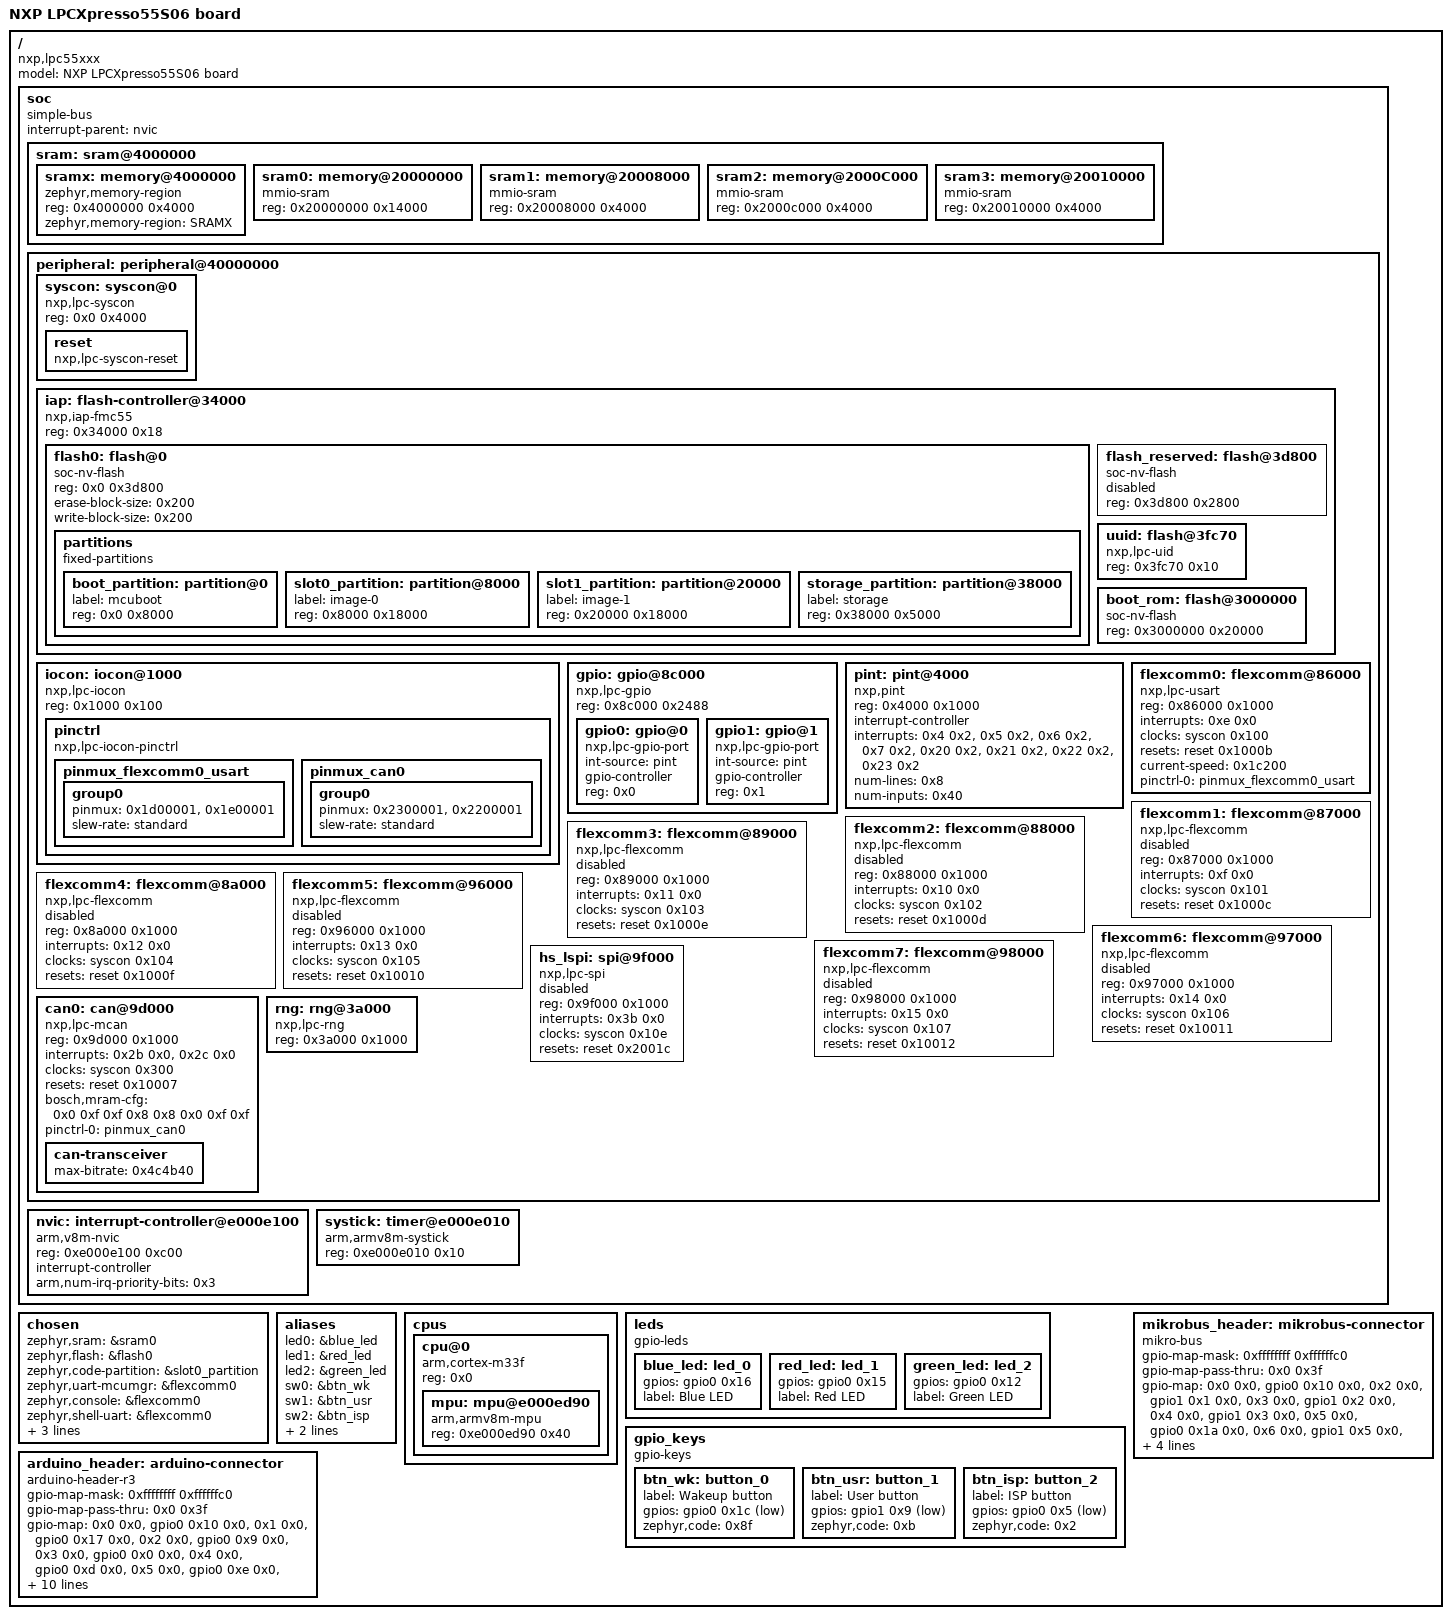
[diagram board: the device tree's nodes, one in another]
/dts-v1/;

/* node '/' defined in zephyr/dts/arm/nxp/nxp_lpc55S06_ns.dtsi:7 */
/ {
	#address-cells = < 0x1 >;            /* in zephyr/dts/common/skeleton.dtsi:10 */
	#size-cells = < 0x1 >;               /* in zephyr/dts/common/skeleton.dtsi:11 */
	model = "NXP LPCXpresso55S06 board"; /* in zephyr/boards/nxp/lpcxpresso55s06/lpcxpresso55s06.dts:13 */
	compatible = "nxp,lpc55xxx",
	             "nxp,lpc";              /* in zephyr/boards/nxp/lpcxpresso55s06/lpcxpresso55s06.dts:14 */

	/* node '/soc' defined in zephyr/dts/arm/nxp/nxp_lpc55S06_ns.dtsi:8 */
	soc {
		#address-cells = < 0x1 >;     /* in zephyr/dts/arm/armv8-m.dtsi:7 */
		#size-cells = < 0x1 >;        /* in zephyr/dts/arm/armv8-m.dtsi:8 */
		compatible = "simple-bus";    /* in zephyr/dts/arm/armv8-m.dtsi:9 */
		interrupt-parent = < &nvic >; /* in zephyr/dts/arm/armv8-m.dtsi:10 */
		ranges;                       /* in zephyr/dts/arm/armv8-m.dtsi:11 */

		/* node '/soc/sram@4000000' defined in zephyr/dts/arm/nxp/nxp_lpc55S06_ns.dtsi:9 */
		sram: sram@4000000 {
			ranges = < 0x4000000 0x4000000 0x20000000 >; /* in zephyr/dts/arm/nxp/nxp_lpc55S06_ns.dtsi:10 */
			#address-cells = < 0x1 >;                    /* in zephyr/dts/arm/nxp/nxp_lpc55S0x_common.dtsi:34 */
			#size-cells = < 0x1 >;                       /* in zephyr/dts/arm/nxp/nxp_lpc55S0x_common.dtsi:35 */

			/* node '/soc/sram@4000000/memory@4000000' defined in zephyr/dts/arm/nxp/nxp_lpc55S0x_common.dtsi:43 */
			sramx: memory@4000000 {
				compatible = "zephyr,memory-region",
				             "mmio-sram";            /* in zephyr/dts/arm/nxp/nxp_lpc55S06_ns.dtsi:22 */
				reg = < 0x4000000 0x4000 >;          /* in zephyr/dts/arm/nxp/nxp_lpc55S06_ns.dtsi:23 */
				zephyr,memory-region = "SRAMX";      /* in zephyr/dts/arm/nxp/nxp_lpc55S06_ns.dtsi:24 */
			};

			/* node '/soc/sram@4000000/memory@20000000' defined in zephyr/dts/arm/nxp/nxp_lpc55S0x_common.dtsi:48 */
			sram0: memory@20000000 {
				compatible = "mmio-sram";     /* in zephyr/dts/arm/nxp/nxp_lpc55S06_ns.dtsi:36 */
				reg = < 0x20000000 0x14000 >; /* in zephyr/dts/arm/nxp/nxp_lpc55S06_ns.dtsi:37 */
			};

			/* node '/soc/sram@4000000/memory@20008000' defined in zephyr/dts/arm/nxp/nxp_lpc55S0x_common.dtsi:53 */
			sram1: memory@20008000 {
				compatible = "mmio-sram";    /* in zephyr/dts/arm/nxp/nxp_lpc55S0x_common.dtsi:54 */
				reg = < 0x20008000 0x4000 >; /* in zephyr/dts/arm/nxp/nxp_lpc55S0x_common.dtsi:55 */
			};

			/* node '/soc/sram@4000000/memory@2000C000' defined in zephyr/dts/arm/nxp/nxp_lpc55S0x_common.dtsi:58 */
			sram2: memory@2000C000 {
				compatible = "mmio-sram";    /* in zephyr/dts/arm/nxp/nxp_lpc55S0x_common.dtsi:59 */
				reg = < 0x2000c000 0x4000 >; /* in zephyr/dts/arm/nxp/nxp_lpc55S0x_common.dtsi:60 */
			};

			/* node '/soc/sram@4000000/memory@20010000' defined in zephyr/dts/arm/nxp/nxp_lpc55S0x_common.dtsi:63 */
			sram3: memory@20010000 {
				compatible = "mmio-sram";    /* in zephyr/dts/arm/nxp/nxp_lpc55S0x_common.dtsi:64 */
				reg = < 0x20010000 0x4000 >; /* in zephyr/dts/arm/nxp/nxp_lpc55S0x_common.dtsi:65 */
			};
		};

		/* node '/soc/peripheral@40000000' defined in zephyr/dts/arm/nxp/nxp_lpc55S06_ns.dtsi:13 */
		peripheral: peripheral@40000000 {
			ranges = < 0x0 0x40000000 0x10000000 >; /* in zephyr/dts/arm/nxp/nxp_lpc55S06_ns.dtsi:14 */
			#address-cells = < 0x1 >;               /* in zephyr/dts/arm/nxp/nxp_lpc55S0x_common.dtsi:70 */
			#size-cells = < 0x1 >;                  /* in zephyr/dts/arm/nxp/nxp_lpc55S0x_common.dtsi:71 */

			/* node '/soc/peripheral@40000000/syscon@0' defined in zephyr/dts/arm/nxp/nxp_lpc55S0x_common.dtsi:73 */
			syscon: syscon@0 {
				compatible = "nxp,lpc-syscon"; /* in zephyr/dts/arm/nxp/nxp_lpc55S0x_common.dtsi:74 */
				reg = < 0x0 0x4000 >;          /* in zephyr/dts/arm/nxp/nxp_lpc55S0x_common.dtsi:75 */
				#clock-cells = < 0x1 >;        /* in zephyr/dts/arm/nxp/nxp_lpc55S0x_common.dtsi:76 */
				phandle = < 0x2 >;             /* in zephyr/dts/arm/nxp/nxp_lpc55S0x_common.dtsi:166 */

				/* node '/soc/peripheral@40000000/syscon@0/reset' defined in zephyr/dts/arm/nxp/nxp_lpc55S0x_common.dtsi:78 */
				reset: reset {
					compatible = "nxp,lpc-syscon-reset"; /* in zephyr/dts/arm/nxp/nxp_lpc55S0x_common.dtsi:79 */
					#reset-cells = < 0x1 >;              /* in zephyr/dts/arm/nxp/nxp_lpc55S0x_common.dtsi:80 */
					phandle = < 0x3 >;                   /* in zephyr/dts/arm/nxp/nxp_lpc55S0x_common.dtsi:167 */
				};
			};

			/* node '/soc/peripheral@40000000/flash-controller@34000' defined in zephyr/dts/arm/nxp/nxp_lpc55S0x_common.dtsi:84 */
			iap: flash-controller@34000 {
				compatible = "nxp,iap-fmc55"; /* in zephyr/dts/arm/nxp/nxp_lpc55S0x_common.dtsi:85 */
				reg = < 0x34000 0x18 >;       /* in zephyr/dts/arm/nxp/nxp_lpc55S0x_common.dtsi:86 */
				#address-cells = < 0x1 >;     /* in zephyr/dts/arm/nxp/nxp_lpc55S0x_common.dtsi:88 */
				#size-cells = < 0x1 >;        /* in zephyr/dts/arm/nxp/nxp_lpc55S0x_common.dtsi:89 */
				status = "okay";              /* in zephyr/dts/arm/nxp/nxp_lpc55S06_ns.dtsi:28 */

				/* node '/soc/peripheral@40000000/flash-controller@34000/flash@0' defined in zephyr/dts/arm/nxp/nxp_lpc55S0x_common.dtsi:91 */
				flash0: flash@0 {
					compatible = "soc-nv-flash";  /* in zephyr/dts/arm/nxp/nxp_lpc55S0x_common.dtsi:92 */
					reg = < 0x0 0x3d800 >;        /* in zephyr/dts/arm/nxp/nxp_lpc55S0x_common.dtsi:93 */
					erase-block-size = < 0x200 >; /* in zephyr/dts/arm/nxp/nxp_lpc55S0x_common.dtsi:94 */
					write-block-size = < 0x200 >; /* in zephyr/dts/arm/nxp/nxp_lpc55S0x_common.dtsi:95 */

					/* node '/soc/peripheral@40000000/flash-controller@34000/flash@0/partitions' defined in zephyr/boards/nxp/lpcxpresso55s06/lpcxpresso55s06_common.dtsi:129 */
					partitions {
						compatible = "fixed-partitions"; /* in zephyr/boards/nxp/lpcxpresso55s06/lpcxpresso55s06_common.dtsi:130 */
						#address-cells = < 0x1 >;        /* in zephyr/boards/nxp/lpcxpresso55s06/lpcxpresso55s06_common.dtsi:131 */
						#size-cells = < 0x1 >;           /* in zephyr/boards/nxp/lpcxpresso55s06/lpcxpresso55s06_common.dtsi:132 */

						/* node '/soc/peripheral@40000000/flash-controller@34000/flash@0/partitions/partition@0' defined in zephyr/boards/nxp/lpcxpresso55s06/lpcxpresso55s06_common.dtsi:134 */
						boot_partition: partition@0 {
							label = "mcuboot";    /* in zephyr/boards/nxp/lpcxpresso55s06/lpcxpresso55s06_common.dtsi:135 */
							reg = < 0x0 0x8000 >; /* in zephyr/boards/nxp/lpcxpresso55s06/lpcxpresso55s06_common.dtsi:136 */
						};

						/* node '/soc/peripheral@40000000/flash-controller@34000/flash@0/partitions/partition@8000' defined in zephyr/boards/nxp/lpcxpresso55s06/lpcxpresso55s06_common.dtsi:139 */
						slot0_partition: partition@8000 {
							label = "image-0";        /* in zephyr/boards/nxp/lpcxpresso55s06/lpcxpresso55s06_common.dtsi:140 */
							reg = < 0x8000 0x18000 >; /* in zephyr/boards/nxp/lpcxpresso55s06/lpcxpresso55s06_common.dtsi:141 */
						};

						/* node '/soc/peripheral@40000000/flash-controller@34000/flash@0/partitions/partition@20000' defined in zephyr/boards/nxp/lpcxpresso55s06/lpcxpresso55s06_common.dtsi:144 */
						slot1_partition: partition@20000 {
							label = "image-1";         /* in zephyr/boards/nxp/lpcxpresso55s06/lpcxpresso55s06_common.dtsi:145 */
							reg = < 0x20000 0x18000 >; /* in zephyr/boards/nxp/lpcxpresso55s06/lpcxpresso55s06_common.dtsi:146 */
						};

						/* node '/soc/peripheral@40000000/flash-controller@34000/flash@0/partitions/partition@38000' defined in zephyr/boards/nxp/lpcxpresso55s06/lpcxpresso55s06_common.dtsi:149 */
						storage_partition: partition@38000 {
							label = "storage";        /* in zephyr/boards/nxp/lpcxpresso55s06/lpcxpresso55s06_common.dtsi:150 */
							reg = < 0x38000 0x5000 >; /* in zephyr/boards/nxp/lpcxpresso55s06/lpcxpresso55s06_common.dtsi:151 */
						};
					};
				};

				/* node '/soc/peripheral@40000000/flash-controller@34000/flash@3d800' defined in zephyr/dts/arm/nxp/nxp_lpc55S0x_common.dtsi:98 */
				flash_reserved: flash@3d800 {
					compatible = "soc-nv-flash"; /* in zephyr/dts/arm/nxp/nxp_lpc55S0x_common.dtsi:99 */
					reg = < 0x3d800 0x2800 >;    /* in zephyr/dts/arm/nxp/nxp_lpc55S0x_common.dtsi:100 */
					status = "disabled";         /* in zephyr/dts/arm/nxp/nxp_lpc55S0x_common.dtsi:101 */
				};

				/* node '/soc/peripheral@40000000/flash-controller@34000/flash@3fc70' defined in zephyr/dts/arm/nxp/nxp_lpc55S0x_common.dtsi:104 */
				uuid: flash@3fc70 {
					compatible = "nxp,lpc-uid"; /* in zephyr/dts/arm/nxp/nxp_lpc55S0x_common.dtsi:105 */
					reg = < 0x3fc70 0x10 >;     /* in zephyr/dts/arm/nxp/nxp_lpc55S0x_common.dtsi:106 */
				};

				/* node '/soc/peripheral@40000000/flash-controller@34000/flash@3000000' defined in zephyr/dts/arm/nxp/nxp_lpc55S0x_common.dtsi:109 */
				boot_rom: flash@3000000 {
					compatible = "soc-nv-flash"; /* in zephyr/dts/arm/nxp/nxp_lpc55S0x_common.dtsi:110 */
					reg = < 0x3000000 0x20000 >; /* in zephyr/dts/arm/nxp/nxp_lpc55S0x_common.dtsi:111 */
				};
			};

			/* node '/soc/peripheral@40000000/iocon@1000' defined in zephyr/dts/arm/nxp/nxp_lpc55S0x_common.dtsi:115 */
			iocon: iocon@1000 {
				compatible = "nxp,lpc-iocon";  /* in zephyr/dts/arm/nxp/nxp_lpc55S0x_common.dtsi:116 */
				reg = < 0x1000 0x100 >;        /* in zephyr/dts/arm/nxp/nxp_lpc55S0x_common.dtsi:117 */
				#address-cells = < 0x1 >;      /* in zephyr/dts/arm/nxp/nxp_lpc55S0x_common.dtsi:118 */
				#size-cells = < 0x1 >;         /* in zephyr/dts/arm/nxp/nxp_lpc55S0x_common.dtsi:119 */
				ranges = < 0x0 0x1000 0x100 >; /* in zephyr/dts/arm/nxp/nxp_lpc55S0x_common.dtsi:120 */

				/* node '/soc/peripheral@40000000/iocon@1000/pinctrl' defined in zephyr/dts/arm/nxp/nxp_lpc55S0x_common.dtsi:122 */
				pinctrl: pinctrl {
					compatible = "nxp,lpc-iocon-pinctrl"; /* in zephyr/dts/arm/nxp/nxp_lpc55S0x_common.dtsi:123 */

					/* node '/soc/peripheral@40000000/iocon@1000/pinctrl/pinmux_flexcomm0_usart' defined in zephyr/boards/nxp/lpcxpresso55s06/lpcxpresso55s06-pinctrl.dtsi:12 */
					pinmux_flexcomm0_usart: pinmux_flexcomm0_usart {
						phandle = < 0x4 >; /* in zephyr/boards/nxp/lpcxpresso55s06/lpcxpresso55s06_common.dtsi:161 */

						/* node '/soc/peripheral@40000000/iocon@1000/pinctrl/pinmux_flexcomm0_usart/group0' defined in zephyr/boards/nxp/lpcxpresso55s06/lpcxpresso55s06-pinctrl.dtsi:13 */
						group0 {
							pinmux = < 0x1d00001 >,
							         < 0x1e00001 >; /* in zephyr/boards/nxp/lpcxpresso55s06/lpcxpresso55s06-pinctrl.dtsi:14 */
							slew-rate = "standard"; /* in zephyr/boards/nxp/lpcxpresso55s06/lpcxpresso55s06-pinctrl.dtsi:16 */
						};
					};

					/* node '/soc/peripheral@40000000/iocon@1000/pinctrl/pinmux_can0' defined in zephyr/boards/nxp/lpcxpresso55s06/lpcxpresso55s06-pinctrl.dtsi:20 */
					pinmux_can0: pinmux_can0 {
						phandle = < 0x5 >; /* in zephyr/boards/nxp/lpcxpresso55s06/lpcxpresso55s06_common.dtsi:167 */

						/* node '/soc/peripheral@40000000/iocon@1000/pinctrl/pinmux_can0/group0' defined in zephyr/boards/nxp/lpcxpresso55s06/lpcxpresso55s06-pinctrl.dtsi:21 */
						group0 {
							pinmux = < 0x2300001 >,
							         < 0x2200001 >; /* in zephyr/boards/nxp/lpcxpresso55s06/lpcxpresso55s06-pinctrl.dtsi:22 */
							slew-rate = "standard"; /* in zephyr/boards/nxp/lpcxpresso55s06/lpcxpresso55s06-pinctrl.dtsi:24 */
						};
					};
				};
			};

			/* node '/soc/peripheral@40000000/gpio@8c000' defined in zephyr/dts/arm/nxp/nxp_lpc55S0x_common.dtsi:127 */
			gpio: gpio@8c000 {
				compatible = "nxp,lpc-gpio"; /* in zephyr/dts/arm/nxp/nxp_lpc55S0x_common.dtsi:128 */
				reg = < 0x8c000 0x2488 >;    /* in zephyr/dts/arm/nxp/nxp_lpc55S0x_common.dtsi:129 */
				#address-cells = < 0x1 >;    /* in zephyr/dts/arm/nxp/nxp_lpc55S0x_common.dtsi:130 */
				#size-cells = < 0x0 >;       /* in zephyr/dts/arm/nxp/nxp_lpc55S0x_common.dtsi:131 */

				/* node '/soc/peripheral@40000000/gpio@8c000/gpio@0' defined in zephyr/dts/arm/nxp/nxp_lpc55S0x_common.dtsi:133 */
				gpio0: gpio@0 {
					compatible = "nxp,lpc-gpio-port"; /* in zephyr/dts/arm/nxp/nxp_lpc55S0x_common.dtsi:134 */
					int-source = "pint";              /* in zephyr/dts/arm/nxp/nxp_lpc55S0x_common.dtsi:135 */
					gpio-controller;                  /* in zephyr/dts/arm/nxp/nxp_lpc55S0x_common.dtsi:136 */
					#gpio-cells = < 0x2 >;            /* in zephyr/dts/arm/nxp/nxp_lpc55S0x_common.dtsi:137 */
					reg = < 0x0 >;                    /* in zephyr/dts/arm/nxp/nxp_lpc55S0x_common.dtsi:138 */
					phandle = < 0x6 >;                /* in zephyr/boards/nxp/lpcxpresso55s06/lpcxpresso55s06_common.dtsi:40 */
				};

				/* node '/soc/peripheral@40000000/gpio@8c000/gpio@1' defined in zephyr/dts/arm/nxp/nxp_lpc55S0x_common.dtsi:141 */
				gpio1: gpio@1 {
					compatible = "nxp,lpc-gpio-port"; /* in zephyr/dts/arm/nxp/nxp_lpc55S0x_common.dtsi:142 */
					int-source = "pint";              /* in zephyr/dts/arm/nxp/nxp_lpc55S0x_common.dtsi:143 */
					gpio-controller;                  /* in zephyr/dts/arm/nxp/nxp_lpc55S0x_common.dtsi:144 */
					#gpio-cells = < 0x2 >;            /* in zephyr/dts/arm/nxp/nxp_lpc55S0x_common.dtsi:145 */
					reg = < 0x1 >;                    /* in zephyr/dts/arm/nxp/nxp_lpc55S0x_common.dtsi:146 */
					phandle = < 0x7 >;                /* in zephyr/boards/nxp/lpcxpresso55s06/lpcxpresso55s06_common.dtsi:66 */
				};
			};

			/* node '/soc/peripheral@40000000/pint@4000' defined in zephyr/dts/arm/nxp/nxp_lpc55S0x_common.dtsi:150 */
			pint: pint@4000 {
				compatible = "nxp,pint";    /* in zephyr/dts/arm/nxp/nxp_lpc55S0x_common.dtsi:151 */
				reg = < 0x4000 0x1000 >;    /* in zephyr/dts/arm/nxp/nxp_lpc55S0x_common.dtsi:152 */
				interrupt-controller;       /* in zephyr/dts/arm/nxp/nxp_lpc55S0x_common.dtsi:153 */
				#interrupt-cells = < 0x1 >; /* in zephyr/dts/arm/nxp/nxp_lpc55S0x_common.dtsi:154 */
				#address-cells = < 0x0 >;   /* in zephyr/dts/arm/nxp/nxp_lpc55S0x_common.dtsi:155 */
				interrupts = < 0x4 0x2 >,
				             < 0x5 0x2 >,
				             < 0x6 0x2 >,
				             < 0x7 0x2 >,
				             < 0x20 0x2 >,
				             < 0x21 0x2 >,
				             < 0x22 0x2 >,
				             < 0x23 0x2 >;  /* in zephyr/dts/arm/nxp/nxp_lpc55S0x_common.dtsi:156 */
				num-lines = < 0x8 >;        /* in zephyr/dts/arm/nxp/nxp_lpc55S0x_common.dtsi:158 */
				num-inputs = < 0x40 >;      /* in zephyr/dts/arm/nxp/nxp_lpc55S0x_common.dtsi:159 */
			};

			/* node '/soc/peripheral@40000000/flexcomm@86000' defined in zephyr/dts/arm/nxp/nxp_lpc55S0x_common.dtsi:162 */
			flexcomm0: flexcomm@86000 {
				reg = < 0x86000 0x1000 >;                /* in zephyr/dts/arm/nxp/nxp_lpc55S0x_common.dtsi:164 */
				interrupts = < 0xe 0x0 >;                /* in zephyr/dts/arm/nxp/nxp_lpc55S0x_common.dtsi:165 */
				clocks = < &syscon 0x100 >;              /* in zephyr/dts/arm/nxp/nxp_lpc55S0x_common.dtsi:166 */
				resets = < &reset 0x1000b >;             /* in zephyr/dts/arm/nxp/nxp_lpc55S0x_common.dtsi:167 */
				status = "okay";                         /* in zephyr/boards/nxp/lpcxpresso55s06/lpcxpresso55s06_common.dtsi:158 */
				compatible = "nxp,lpc-usart";            /* in zephyr/boards/nxp/lpcxpresso55s06/lpcxpresso55s06_common.dtsi:159 */
				current-speed = < 0x1c200 >;             /* in zephyr/boards/nxp/lpcxpresso55s06/lpcxpresso55s06_common.dtsi:160 */
				pinctrl-0 = < &pinmux_flexcomm0_usart >; /* in zephyr/boards/nxp/lpcxpresso55s06/lpcxpresso55s06_common.dtsi:161 */
				pinctrl-names = "default";               /* in zephyr/boards/nxp/lpcxpresso55s06/lpcxpresso55s06_common.dtsi:162 */
			};

			/* node '/soc/peripheral@40000000/flexcomm@87000' defined in zephyr/dts/arm/nxp/nxp_lpc55S0x_common.dtsi:171 */
			flexcomm1: flexcomm@87000 {
				compatible = "nxp,lpc-flexcomm"; /* in zephyr/dts/arm/nxp/nxp_lpc55S0x_common.dtsi:172 */
				reg = < 0x87000 0x1000 >;        /* in zephyr/dts/arm/nxp/nxp_lpc55S0x_common.dtsi:173 */
				interrupts = < 0xf 0x0 >;        /* in zephyr/dts/arm/nxp/nxp_lpc55S0x_common.dtsi:174 */
				clocks = < &syscon 0x101 >;      /* in zephyr/dts/arm/nxp/nxp_lpc55S0x_common.dtsi:175 */
				resets = < &reset 0x1000c >;     /* in zephyr/dts/arm/nxp/nxp_lpc55S0x_common.dtsi:176 */
				status = "disabled";             /* in zephyr/dts/arm/nxp/nxp_lpc55S0x_common.dtsi:177 */
			};

			/* node '/soc/peripheral@40000000/flexcomm@88000' defined in zephyr/dts/arm/nxp/nxp_lpc55S0x_common.dtsi:180 */
			flexcomm2: flexcomm@88000 {
				compatible = "nxp,lpc-flexcomm"; /* in zephyr/dts/arm/nxp/nxp_lpc55S0x_common.dtsi:181 */
				reg = < 0x88000 0x1000 >;        /* in zephyr/dts/arm/nxp/nxp_lpc55S0x_common.dtsi:182 */
				interrupts = < 0x10 0x0 >;       /* in zephyr/dts/arm/nxp/nxp_lpc55S0x_common.dtsi:183 */
				clocks = < &syscon 0x102 >;      /* in zephyr/dts/arm/nxp/nxp_lpc55S0x_common.dtsi:184 */
				resets = < &reset 0x1000d >;     /* in zephyr/dts/arm/nxp/nxp_lpc55S0x_common.dtsi:185 */
				status = "disabled";             /* in zephyr/dts/arm/nxp/nxp_lpc55S0x_common.dtsi:186 */
			};

			/* node '/soc/peripheral@40000000/flexcomm@89000' defined in zephyr/dts/arm/nxp/nxp_lpc55S0x_common.dtsi:189 */
			flexcomm3: flexcomm@89000 {
				compatible = "nxp,lpc-flexcomm"; /* in zephyr/dts/arm/nxp/nxp_lpc55S0x_common.dtsi:190 */
				reg = < 0x89000 0x1000 >;        /* in zephyr/dts/arm/nxp/nxp_lpc55S0x_common.dtsi:191 */
				interrupts = < 0x11 0x0 >;       /* in zephyr/dts/arm/nxp/nxp_lpc55S0x_common.dtsi:192 */
				clocks = < &syscon 0x103 >;      /* in zephyr/dts/arm/nxp/nxp_lpc55S0x_common.dtsi:193 */
				resets = < &reset 0x1000e >;     /* in zephyr/dts/arm/nxp/nxp_lpc55S0x_common.dtsi:194 */
				status = "disabled";             /* in zephyr/dts/arm/nxp/nxp_lpc55S0x_common.dtsi:195 */
			};

			/* node '/soc/peripheral@40000000/flexcomm@8a000' defined in zephyr/dts/arm/nxp/nxp_lpc55S0x_common.dtsi:198 */
			flexcomm4: flexcomm@8a000 {
				compatible = "nxp,lpc-flexcomm"; /* in zephyr/dts/arm/nxp/nxp_lpc55S0x_common.dtsi:199 */
				reg = < 0x8a000 0x1000 >;        /* in zephyr/dts/arm/nxp/nxp_lpc55S0x_common.dtsi:200 */
				interrupts = < 0x12 0x0 >;       /* in zephyr/dts/arm/nxp/nxp_lpc55S0x_common.dtsi:201 */
				clocks = < &syscon 0x104 >;      /* in zephyr/dts/arm/nxp/nxp_lpc55S0x_common.dtsi:202 */
				resets = < &reset 0x1000f >;     /* in zephyr/dts/arm/nxp/nxp_lpc55S0x_common.dtsi:203 */
				status = "disabled";             /* in zephyr/dts/arm/nxp/nxp_lpc55S0x_common.dtsi:204 */
			};

			/* node '/soc/peripheral@40000000/flexcomm@96000' defined in zephyr/dts/arm/nxp/nxp_lpc55S0x_common.dtsi:207 */
			flexcomm5: flexcomm@96000 {
				compatible = "nxp,lpc-flexcomm"; /* in zephyr/dts/arm/nxp/nxp_lpc55S0x_common.dtsi:208 */
				reg = < 0x96000 0x1000 >;        /* in zephyr/dts/arm/nxp/nxp_lpc55S0x_common.dtsi:209 */
				interrupts = < 0x13 0x0 >;       /* in zephyr/dts/arm/nxp/nxp_lpc55S0x_common.dtsi:210 */
				clocks = < &syscon 0x105 >;      /* in zephyr/dts/arm/nxp/nxp_lpc55S0x_common.dtsi:211 */
				resets = < &reset 0x10010 >;     /* in zephyr/dts/arm/nxp/nxp_lpc55S0x_common.dtsi:212 */
				status = "disabled";             /* in zephyr/dts/arm/nxp/nxp_lpc55S0x_common.dtsi:213 */
			};

			/* node '/soc/peripheral@40000000/flexcomm@97000' defined in zephyr/dts/arm/nxp/nxp_lpc55S0x_common.dtsi:216 */
			flexcomm6: flexcomm@97000 {
				compatible = "nxp,lpc-flexcomm"; /* in zephyr/dts/arm/nxp/nxp_lpc55S0x_common.dtsi:217 */
				reg = < 0x97000 0x1000 >;        /* in zephyr/dts/arm/nxp/nxp_lpc55S0x_common.dtsi:218 */
				interrupts = < 0x14 0x0 >;       /* in zephyr/dts/arm/nxp/nxp_lpc55S0x_common.dtsi:219 */
				clocks = < &syscon 0x106 >;      /* in zephyr/dts/arm/nxp/nxp_lpc55S0x_common.dtsi:220 */
				resets = < &reset 0x10011 >;     /* in zephyr/dts/arm/nxp/nxp_lpc55S0x_common.dtsi:221 */
				status = "disabled";             /* in zephyr/dts/arm/nxp/nxp_lpc55S0x_common.dtsi:222 */
			};

			/* node '/soc/peripheral@40000000/flexcomm@98000' defined in zephyr/dts/arm/nxp/nxp_lpc55S0x_common.dtsi:225 */
			flexcomm7: flexcomm@98000 {
				compatible = "nxp,lpc-flexcomm"; /* in zephyr/dts/arm/nxp/nxp_lpc55S0x_common.dtsi:226 */
				reg = < 0x98000 0x1000 >;        /* in zephyr/dts/arm/nxp/nxp_lpc55S0x_common.dtsi:227 */
				interrupts = < 0x15 0x0 >;       /* in zephyr/dts/arm/nxp/nxp_lpc55S0x_common.dtsi:228 */
				clocks = < &syscon 0x107 >;      /* in zephyr/dts/arm/nxp/nxp_lpc55S0x_common.dtsi:229 */
				resets = < &reset 0x10012 >;     /* in zephyr/dts/arm/nxp/nxp_lpc55S0x_common.dtsi:230 */
				status = "disabled";             /* in zephyr/dts/arm/nxp/nxp_lpc55S0x_common.dtsi:231 */
			};

			/* node '/soc/peripheral@40000000/spi@9f000' defined in zephyr/dts/arm/nxp/nxp_lpc55S0x_common.dtsi:234 */
			hs_lspi: spi@9f000 {
				compatible = "nxp,lpc-spi";  /* in zephyr/dts/arm/nxp/nxp_lpc55S0x_common.dtsi:235 */
				reg = < 0x9f000 0x1000 >;    /* in zephyr/dts/arm/nxp/nxp_lpc55S0x_common.dtsi:236 */
				interrupts = < 0x3b 0x0 >;   /* in zephyr/dts/arm/nxp/nxp_lpc55S0x_common.dtsi:237 */
				clocks = < &syscon 0x10e >;  /* in zephyr/dts/arm/nxp/nxp_lpc55S0x_common.dtsi:238 */
				resets = < &reset 0x2001c >; /* in zephyr/dts/arm/nxp/nxp_lpc55S0x_common.dtsi:239 */
				status = "disabled";         /* in zephyr/dts/arm/nxp/nxp_lpc55S0x_common.dtsi:240 */
				#address-cells = < 0x1 >;    /* in zephyr/dts/arm/nxp/nxp_lpc55S0x_common.dtsi:241 */
				#size-cells = < 0x0 >;       /* in zephyr/dts/arm/nxp/nxp_lpc55S0x_common.dtsi:242 */
			};

			/* node '/soc/peripheral@40000000/can@9d000' defined in zephyr/dts/arm/nxp/nxp_lpc55S0x_common.dtsi:245 */
			can0: can@9d000 {
				compatible = "nxp,lpc-mcan";                          /* in zephyr/dts/arm/nxp/nxp_lpc55S0x_common.dtsi:246 */
				reg = < 0x9d000 0x1000 >;                             /* in zephyr/dts/arm/nxp/nxp_lpc55S0x_common.dtsi:247 */
				interrupts = < 0x2b 0x0 >,
				             < 0x2c 0x0 >;                            /* in zephyr/dts/arm/nxp/nxp_lpc55S0x_common.dtsi:248 */
				interrupt-names = "int0",
				                  "int1";                             /* in zephyr/dts/arm/nxp/nxp_lpc55S0x_common.dtsi:249 */
				clocks = < &syscon 0x300 >;                           /* in zephyr/dts/arm/nxp/nxp_lpc55S0x_common.dtsi:250 */
				resets = < &reset 0x10007 >;                          /* in zephyr/dts/arm/nxp/nxp_lpc55S0x_common.dtsi:251 */
				bosch,mram-cfg = < 0x0 0xf 0xf 0x8 0x8 0x0 0xf 0xf >; /* in zephyr/dts/arm/nxp/nxp_lpc55S0x_common.dtsi:252 */
				status = "okay";                                      /* in zephyr/boards/nxp/lpcxpresso55s06/lpcxpresso55s06_common.dtsi:166 */
				pinctrl-0 = < &pinmux_can0 >;                         /* in zephyr/boards/nxp/lpcxpresso55s06/lpcxpresso55s06_common.dtsi:167 */
				pinctrl-names = "default";                            /* in zephyr/boards/nxp/lpcxpresso55s06/lpcxpresso55s06_common.dtsi:168 */

				/* node '/soc/peripheral@40000000/can@9d000/can-transceiver' defined in zephyr/boards/nxp/lpcxpresso55s06/lpcxpresso55s06_common.dtsi:170 */
				can-transceiver {
					max-bitrate = < 0x4c4b40 >; /* in zephyr/boards/nxp/lpcxpresso55s06/lpcxpresso55s06_common.dtsi:171 */
				};
			};

			/* node '/soc/peripheral@40000000/rng@3a000' defined in zephyr/dts/arm/nxp/nxp_lpc55S0x_common.dtsi:256 */
			rng: rng@3a000 {
				compatible = "nxp,lpc-rng"; /* in zephyr/dts/arm/nxp/nxp_lpc55S0x_common.dtsi:257 */
				reg = < 0x3a000 0x1000 >;   /* in zephyr/dts/arm/nxp/nxp_lpc55S0x_common.dtsi:258 */
				status = "okay";            /* in zephyr/dts/arm/nxp/nxp_lpc55S0x_common.dtsi:259 */
			};
		};

		/* node '/soc/interrupt-controller@e000e100' defined in zephyr/dts/arm/armv8-m.dtsi:13 */
		nvic: interrupt-controller@e000e100 {
			#address-cells = < 0x1 >;            /* in zephyr/dts/arm/armv8-m.dtsi:14 */
			compatible = "arm,v8m-nvic";         /* in zephyr/dts/arm/armv8-m.dtsi:15 */
			reg = < 0xe000e100 0xc00 >;          /* in zephyr/dts/arm/armv8-m.dtsi:16 */
			interrupt-controller;                /* in zephyr/dts/arm/armv8-m.dtsi:17 */
			#interrupt-cells = < 0x2 >;          /* in zephyr/dts/arm/armv8-m.dtsi:18 */
			arm,num-irq-priority-bits = < 0x3 >; /* in zephyr/dts/arm/nxp/nxp_lpc55S0x_common.dtsi:264 */
			phandle = < 0x1 >;                   /* in zephyr/dts/arm/armv8-m.dtsi:10 */
		};

		/* node '/soc/timer@e000e010' defined in zephyr/dts/arm/armv8-m.dtsi:21 */
		systick: timer@e000e010 {
			compatible = "arm,armv8m-systick"; /* in zephyr/dts/arm/armv8-m.dtsi:22 */
			reg = < 0xe000e010 0x10 >;         /* in zephyr/dts/arm/armv8-m.dtsi:23 */
		};
	};

	/* node '/chosen' defined in zephyr/dts/common/skeleton.dtsi:13 */
	chosen {
		zephyr,sram = &sram0;                     /* in zephyr/boards/nxp/lpcxpresso55s06/lpcxpresso55s06_common.dtsi:14 */
		zephyr,flash = &flash0;                   /* in zephyr/boards/nxp/lpcxpresso55s06/lpcxpresso55s06_common.dtsi:15 */
		zephyr,code-partition = &slot0_partition; /* in zephyr/boards/nxp/lpcxpresso55s06/lpcxpresso55s06_common.dtsi:16 */
		zephyr,uart-mcumgr = &flexcomm0;          /* in zephyr/boards/nxp/lpcxpresso55s06/lpcxpresso55s06_common.dtsi:17 */
		zephyr,console = &flexcomm0;              /* in zephyr/boards/nxp/lpcxpresso55s06/lpcxpresso55s06_common.dtsi:18 */
		zephyr,shell-uart = &flexcomm0;           /* in zephyr/boards/nxp/lpcxpresso55s06/lpcxpresso55s06_common.dtsi:19 */
		zephyr,entropy = &rng;                    /* in zephyr/boards/nxp/lpcxpresso55s06/lpcxpresso55s06_common.dtsi:20 */
		zephyr,flash-controller = &iap;           /* in zephyr/boards/nxp/lpcxpresso55s06/lpcxpresso55s06_common.dtsi:21 */
		zephyr,canbus = &can0;                    /* in zephyr/boards/nxp/lpcxpresso55s06/lpcxpresso55s06_common.dtsi:22 */
	};

	/* node '/aliases' defined in zephyr/dts/common/skeleton.dtsi:15 */
	aliases {
		led0 = &blue_led;          /* in zephyr/boards/nxp/lpcxpresso55s06/lpcxpresso55s06_common.dtsi:26 */
		led1 = &red_led;           /* in zephyr/boards/nxp/lpcxpresso55s06/lpcxpresso55s06_common.dtsi:27 */
		led2 = &green_led;         /* in zephyr/boards/nxp/lpcxpresso55s06/lpcxpresso55s06_common.dtsi:28 */
		sw0 = &btn_wk;             /* in zephyr/boards/nxp/lpcxpresso55s06/lpcxpresso55s06_common.dtsi:29 */
		sw1 = &btn_usr;            /* in zephyr/boards/nxp/lpcxpresso55s06/lpcxpresso55s06_common.dtsi:30 */
		sw2 = &btn_isp;            /* in zephyr/boards/nxp/lpcxpresso55s06/lpcxpresso55s06_common.dtsi:31 */
		usart-0 = &flexcomm0;      /* in zephyr/boards/nxp/lpcxpresso55s06/lpcxpresso55s06_common.dtsi:32 */
		mcuboot-button0 = &btn_wk; /* in zephyr/boards/nxp/lpcxpresso55s06/lpcxpresso55s06_common.dtsi:33 */
	};

	/* node '/cpus' defined in zephyr/dts/arm/nxp/nxp_lpc55S0x_common.dtsi:15 */
	cpus {
		#address-cells = < 0x1 >; /* in zephyr/dts/arm/nxp/nxp_lpc55S0x_common.dtsi:16 */
		#size-cells = < 0x0 >;    /* in zephyr/dts/arm/nxp/nxp_lpc55S0x_common.dtsi:17 */

		/* node '/cpus/cpu@0' defined in zephyr/dts/arm/nxp/nxp_lpc55S0x_common.dtsi:19 */
		cpu@0 {
			compatible = "arm,cortex-m33f"; /* in zephyr/dts/arm/nxp/nxp_lpc55S0x_common.dtsi:20 */
			reg = < 0x0 >;                  /* in zephyr/dts/arm/nxp/nxp_lpc55S0x_common.dtsi:21 */
			#address-cells = < 0x1 >;       /* in zephyr/dts/arm/nxp/nxp_lpc55S0x_common.dtsi:22 */
			#size-cells = < 0x1 >;          /* in zephyr/dts/arm/nxp/nxp_lpc55S0x_common.dtsi:23 */

			/* node '/cpus/cpu@0/mpu@e000ed90' defined in zephyr/dts/arm/nxp/nxp_lpc55S0x_common.dtsi:25 */
			mpu: mpu@e000ed90 {
				compatible = "arm,armv8m-mpu"; /* in zephyr/dts/arm/nxp/nxp_lpc55S0x_common.dtsi:26 */
				reg = < 0xe000ed90 0x40 >;     /* in zephyr/dts/arm/nxp/nxp_lpc55S0x_common.dtsi:27 */
			};
		};
	};

	/* node '/leds' defined in zephyr/boards/nxp/lpcxpresso55s06/lpcxpresso55s06_common.dtsi:36 */
	leds {
		compatible = "gpio-leds"; /* in zephyr/boards/nxp/lpcxpresso55s06/lpcxpresso55s06_common.dtsi:37 */

		/* node '/leds/led_0' defined in zephyr/boards/nxp/lpcxpresso55s06/lpcxpresso55s06_common.dtsi:39 */
		blue_led: led_0 {
			gpios = < &gpio0 0x16 0x0 >; /* in zephyr/boards/nxp/lpcxpresso55s06/lpcxpresso55s06_common.dtsi:40 */
			label = "Blue LED";          /* in zephyr/boards/nxp/lpcxpresso55s06/lpcxpresso55s06_common.dtsi:41 */
		};

		/* node '/leds/led_1' defined in zephyr/boards/nxp/lpcxpresso55s06/lpcxpresso55s06_common.dtsi:44 */
		red_led: led_1 {
			gpios = < &gpio0 0x15 0x0 >; /* in zephyr/boards/nxp/lpcxpresso55s06/lpcxpresso55s06_common.dtsi:45 */
			label = "Red LED";           /* in zephyr/boards/nxp/lpcxpresso55s06/lpcxpresso55s06_common.dtsi:46 */
		};

		/* node '/leds/led_2' defined in zephyr/boards/nxp/lpcxpresso55s06/lpcxpresso55s06_common.dtsi:49 */
		green_led: led_2 {
			gpios = < &gpio0 0x12 0x0 >; /* in zephyr/boards/nxp/lpcxpresso55s06/lpcxpresso55s06_common.dtsi:50 */
			label = "Green LED";         /* in zephyr/boards/nxp/lpcxpresso55s06/lpcxpresso55s06_common.dtsi:51 */
		};
	};

	/* node '/gpio_keys' defined in zephyr/boards/nxp/lpcxpresso55s06/lpcxpresso55s06_common.dtsi:55 */
	gpio_keys {
		compatible = "gpio-keys"; /* in zephyr/boards/nxp/lpcxpresso55s06/lpcxpresso55s06_common.dtsi:56 */

		/* node '/gpio_keys/button_0' defined in zephyr/boards/nxp/lpcxpresso55s06/lpcxpresso55s06_common.dtsi:58 */
		btn_wk: button_0 {
			label = "Wakeup button";     /* in zephyr/boards/nxp/lpcxpresso55s06/lpcxpresso55s06_common.dtsi:59 */
			gpios = < &gpio0 0x1c 0x1 >; /* in zephyr/boards/nxp/lpcxpresso55s06/lpcxpresso55s06_common.dtsi:60 */
			zephyr,code = < 0x8f >;      /* in zephyr/boards/nxp/lpcxpresso55s06/lpcxpresso55s06_common.dtsi:61 */
		};

		/* node '/gpio_keys/button_1' defined in zephyr/boards/nxp/lpcxpresso55s06/lpcxpresso55s06_common.dtsi:64 */
		btn_usr: button_1 {
			label = "User button";      /* in zephyr/boards/nxp/lpcxpresso55s06/lpcxpresso55s06_common.dtsi:65 */
			gpios = < &gpio1 0x9 0x1 >; /* in zephyr/boards/nxp/lpcxpresso55s06/lpcxpresso55s06_common.dtsi:66 */
			zephyr,code = < 0xb >;      /* in zephyr/boards/nxp/lpcxpresso55s06/lpcxpresso55s06_common.dtsi:67 */
		};

		/* node '/gpio_keys/button_2' defined in zephyr/boards/nxp/lpcxpresso55s06/lpcxpresso55s06_common.dtsi:70 */
		btn_isp: button_2 {
			label = "ISP button";       /* in zephyr/boards/nxp/lpcxpresso55s06/lpcxpresso55s06_common.dtsi:71 */
			gpios = < &gpio0 0x5 0x1 >; /* in zephyr/boards/nxp/lpcxpresso55s06/lpcxpresso55s06_common.dtsi:72 */
			zephyr,code = < 0x2 >;      /* in zephyr/boards/nxp/lpcxpresso55s06/lpcxpresso55s06_common.dtsi:73 */
		};
	};

	/* node '/mikrobus-connector' defined in zephyr/boards/nxp/lpcxpresso55s06/lpcxpresso55s06_common.dtsi:77 */
	mikrobus_header: mikrobus-connector {
		compatible = "mikro-bus";                  /* in zephyr/boards/nxp/lpcxpresso55s06/lpcxpresso55s06_common.dtsi:78 */
		#gpio-cells = < 0x2 >;                     /* in zephyr/boards/nxp/lpcxpresso55s06/lpcxpresso55s06_common.dtsi:79 */
		gpio-map-mask = < 0xffffffff 0xffffffc0 >; /* in zephyr/boards/nxp/lpcxpresso55s06/lpcxpresso55s06_common.dtsi:80 */
		gpio-map-pass-thru = < 0x0 0x3f >;         /* in zephyr/boards/nxp/lpcxpresso55s06/lpcxpresso55s06_common.dtsi:81 */
		gpio-map = < 0x0 0x0 &gpio0 0x10 0x0 >,
		           < 0x2 0x0 &gpio1 0x1 0x0 >,
		           < 0x3 0x0 &gpio1 0x2 0x0 >,
		           < 0x4 0x0 &gpio1 0x3 0x0 >,
		           < 0x5 0x0 &gpio0 0x1a 0x0 >,
		           < 0x6 0x0 &gpio1 0x5 0x0 >,
		           < 0x7 0x0 &gpio0 0x1c 0x0 >,
		           < 0x8 0x0 &gpio1 0xa 0x0 >,
		           < 0x9 0x0 &gpio1 0xb 0x0 >,
		           < 0xa 0x0 &gpio0 0x18 0x0 >,
		           < 0xb 0x0 &gpio0 0x19 0x0 >;    /* in zephyr/boards/nxp/lpcxpresso55s06/lpcxpresso55s06_common.dtsi:82 */
	};

	/* node '/arduino-connector' defined in zephyr/boards/nxp/lpcxpresso55s06/lpcxpresso55s06_common.dtsi:100 */
	arduino_header: arduino-connector {
		compatible = "arduino-header-r3";          /* in zephyr/boards/nxp/lpcxpresso55s06/lpcxpresso55s06_common.dtsi:101 */
		#gpio-cells = < 0x2 >;                     /* in zephyr/boards/nxp/lpcxpresso55s06/lpcxpresso55s06_common.dtsi:102 */
		gpio-map-mask = < 0xffffffff 0xffffffc0 >; /* in zephyr/boards/nxp/lpcxpresso55s06/lpcxpresso55s06_common.dtsi:103 */
		gpio-map-pass-thru = < 0x0 0x3f >;         /* in zephyr/boards/nxp/lpcxpresso55s06/lpcxpresso55s06_common.dtsi:104 */
		gpio-map = < 0x0 0x0 &gpio0 0x10 0x0 >,
		           < 0x1 0x0 &gpio0 0x17 0x0 >,
		           < 0x2 0x0 &gpio0 0x9 0x0 >,
		           < 0x3 0x0 &gpio0 0x0 0x0 >,
		           < 0x4 0x0 &gpio0 0xd 0x0 >,
		           < 0x5 0x0 &gpio0 0xe 0x0 >,
		           < 0x6 0x0 &gpio1 0xa 0x0 >,
		           < 0x7 0x0 &gpio1 0xb 0x0 >,
		           < 0x8 0x0 &gpio0 0xf 0x0 >,
		           < 0x9 0x0 &gpio0 0x17 0x0 >,
		           < 0xa 0x0 &gpio0 0x16 0x0 >,
		           < 0xb 0x0 &gpio0 0x13 0x0 >,
		           < 0xc 0x0 &gpio0 0x12 0x0 >,
		           < 0xd 0x0 &gpio0 0x2 0x0 >,
		           < 0xe 0x0 &gpio0 0xa 0x0 >,
		           < 0xf 0x0 &gpio0 0x19 0x0 >,
		           < 0x10 0x0 &gpio1 0x1 0x0 >,
		           < 0x11 0x0 &gpio0 0x1a 0x0 >,
		           < 0x12 0x0 &gpio1 0x3 0x0 >,
		           < 0x13 0x0 &gpio1 0x2 0x0 >;    /* in zephyr/boards/nxp/lpcxpresso55s06/lpcxpresso55s06_common.dtsi:105 */
	};
};
